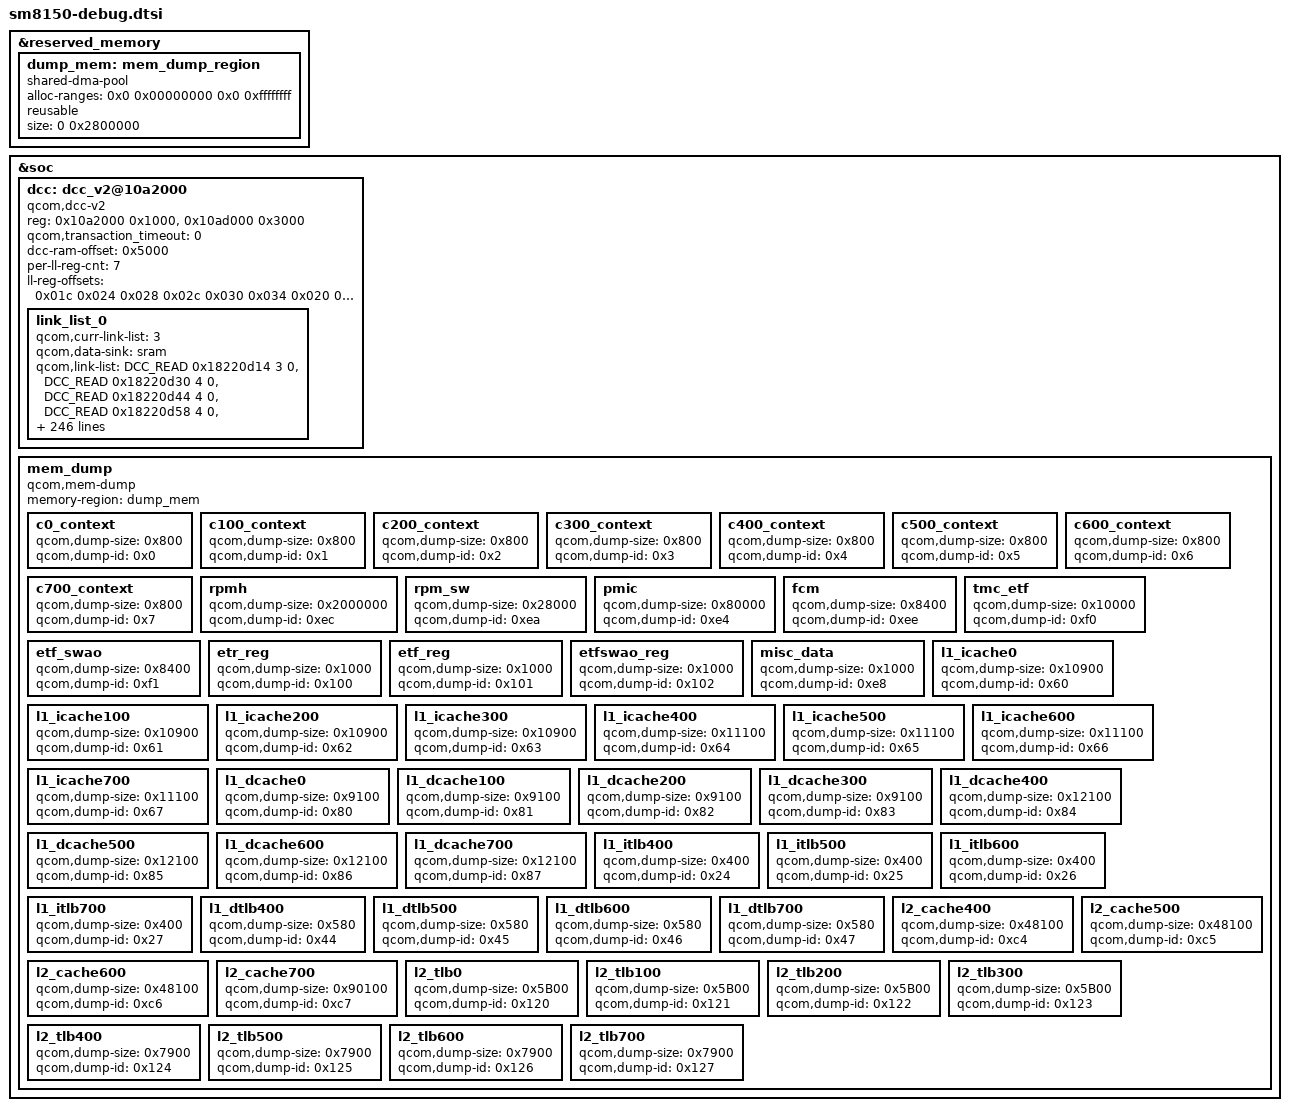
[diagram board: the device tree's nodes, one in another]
#include <dt-bindings/soc/qcom,dcc_v2.h>

&reserved_memory {
	#address-cells = <2>;
	#size-cells = <2>;
	ranges;

	dump_mem: mem_dump_region {
		compatible = "shared-dma-pool";
		alloc-ranges = <0x0 0x00000000 0x0 0xffffffff>;
		reusable;
		size = <0 0x2800000>;
	};
};

&soc {
	dcc: dcc_v2@10a2000 {
		compatible = "qcom,dcc-v2";
		reg = <0x10a2000 0x1000>,
		      <0x10ad000 0x3000>;
		reg-names = "dcc-base", "dcc-ram-base";

		qcom,transaction_timeout = <0>;

		dcc-ram-offset = <0x5000>;

		per-ll-reg-cnt = <7>;
		ll-reg-offsets = <
			0x01c 0x024 0x028 0x02c 0x030 0x034 0x020
			0x09c 0x0a4 0x0a8 0x0ac 0x0b0 0x0b4 0x0a0
			0x11c 0x124 0x128 0x12c 0x130 0x134 0x120
			0x19c 0x1a4 0x1a8 0x1ac 0x1b0 0x1b4 0x1a0
			0x21c 0x224 0x228 0x22c 0x230 0x234 0x220
			0x29c 0x2a4 0x2a8 0x2ac 0x2b0 0x2b4 0x2a0
			0x31c 0x324 0x328 0x32c 0x330 0x334 0x320
			0x39c 0x3a4 0x3a8 0x3ac 0x3b0 0x3b4 0x3a4>;

		link_list_0 {
			qcom,curr-link-list = <3>;
			qcom,data-sink = "sram";
			qcom,link-list = <DCC_READ 0x18220d14 3 0>,
						<DCC_READ 0x18220d30 4 0>,
						<DCC_READ 0x18220d44 4 0>,
						<DCC_READ 0x18220d58 4 0>,
						<DCC_READ 0x18220fb4 3 0>,
						<DCC_READ 0x18220fd0 4 0>,
						<DCC_READ 0x18220fe4 4 0>,
						<DCC_READ 0x18220ff8 4 0>,
						<DCC_READ 0x18220d04 1 0>,
						<DCC_READ 0x18220d00 1 0>,
						<DCC_READ 0x18000024 1 0>,
						<DCC_READ 0x18000040 3 0>,
						<DCC_READ 0x18010024 1 0>,
						<DCC_READ 0x18010040 3 0>,
						<DCC_READ 0x18020024 1 0>,
						<DCC_READ 0x18020040 3 0>,
						<DCC_READ 0x18030024 1 0>,
						<DCC_READ 0x18030040 3 0>,
						<DCC_READ 0x18040024 1 0>,
						<DCC_READ 0x18040040 3 0>,
						<DCC_READ 0x18050024 1 0>,
						<DCC_READ 0x18050040 3 0>,
						<DCC_READ 0x18060024 1 0>,
						<DCC_READ 0x18060040 3 0>,
						<DCC_READ 0x18070024 1 0>,
						<DCC_READ 0x18070040 3 0>,
						<DCC_READ 0x18080104 1 0>,
						<DCC_READ 0x18080168 1 0>,
						<DCC_READ 0x18080198 1 0>,
						<DCC_READ 0x18080128 1 0>,
						<DCC_READ 0x18080024 1 0>,
						<DCC_READ 0x18080040 3 0>,
						<DCC_READ 0x18200400 3 0>,
						<DCC_READ 0x0b201020 2 0>,
						<DCC_READ 0x18101908 1 0>,
						<DCC_READ 0x18101c18 1 0>,
						<DCC_READ 0x18390810 1 0>,
						<DCC_READ 0x18390c50 1 0>,
						<DCC_READ 0x18390814 1 0>,
						<DCC_READ 0x18390c54 1 0>,
						<DCC_READ 0x18390818 1 0>,
						<DCC_READ 0x18390c58 1 0>,
						<DCC_READ 0x18393a84 2 0>,
						<DCC_READ 0x18100908 1 0>,
						<DCC_READ 0x18100c18 1 0>,
						<DCC_READ 0x183a0810 1 0>,
						<DCC_READ 0x183a0c50 1 0>,
						<DCC_READ 0x183a0814 1 0>,
						<DCC_READ 0x183a0c54 1 0>,
						<DCC_READ 0x183a0818 1 0>,
						<DCC_READ 0x183a0c58 1 0>,
						<DCC_READ 0x183a3a84 2 0>,
						<DCC_READ 0x18393500 80 0>,
						<DCC_READ 0x183a3500 80 0>,
						<DCC_READ 0x09050008 1 0>,
						<DCC_READ 0x09050078 1 0>,
						<DCC_READ 0x09601000 1 0>,
						<DCC_READ 0x09601004 1 0>,
						<DCC_READ 0x09602000 1 0>,
						<DCC_READ 0x09602004 1 0>,
						<DCC_READ 0x09603000 1 0>,
						<DCC_READ 0x09603004 1 0>,
						<DCC_READ 0x09604000 1 0>,
						<DCC_READ 0x09604004 1 0>,
						<DCC_READ 0x09605000 1 0>,
						<DCC_READ 0x09605004 1 0>,
						<DCC_READ 0x09606000 1 0>,
						<DCC_READ 0x09606004 1 0>,
						<DCC_READ 0x09607000 1 0>,
						<DCC_READ 0x09607004 1 0>,
						<DCC_READ 0x09608000 1 0>,
						<DCC_READ 0x09608004 1 0>,
						<DCC_READ 0x09609000 1 0>,
						<DCC_READ 0x09609004 1 0>,
						<DCC_READ 0x0960a000 1 0>,
						<DCC_READ 0x0960a004 1 0>,
						<DCC_READ 0x0960b000 1 0>,
						<DCC_READ 0x0960b004 1 0>,
						<DCC_READ 0x0960c000 1 0>,
						<DCC_READ 0x0960c004 1 0>,
						<DCC_READ 0x0960d000 1 0>,
						<DCC_READ 0x0960d004 1 0>,
						<DCC_READ 0x0960e000 1 0>,
						<DCC_READ 0x0960e004 1 0>,
						<DCC_READ 0x0960f000 1 0>,
						<DCC_READ 0x0960f004 1 0>,
						<DCC_READ 0x09610000 1 0>,
						<DCC_READ 0x09610004 1 0>,
						<DCC_READ 0x09611000 1 0>,
						<DCC_READ 0x09611004 1 0>,
						<DCC_READ 0x09612000 1 0>,
						<DCC_READ 0x09612004 1 0>,
						<DCC_READ 0x09613000 1 0>,
						<DCC_READ 0x09613004 1 0>,
						<DCC_READ 0x09614000 1 0>,
						<DCC_READ 0x09614004 1 0>,
						<DCC_READ 0x09615000 1 0>,
						<DCC_READ 0x09615004 1 0>,
						<DCC_READ 0x09616000 1 0>,
						<DCC_READ 0x09616004 1 0>,
						<DCC_READ 0x09617000 1 0>,
						<DCC_READ 0x09617004 1 0>,
						<DCC_READ 0x09618000 1 0>,
						<DCC_READ 0x09618004 1 0>,
						<DCC_READ 0x09619000 1 0>,
						<DCC_READ 0x09619004 1 0>,
						<DCC_READ 0x0961a000 1 0>,
						<DCC_READ 0x0961a004 1 0>,
						<DCC_READ 0x0961b000 1 0>,
						<DCC_READ 0x0961b004 1 0>,
						<DCC_READ 0x0961c000 1 0>,
						<DCC_READ 0x0961c004 1 0>,
						<DCC_READ 0x0961d000 1 0>,
						<DCC_READ 0x0961d004 1 0>,
						<DCC_READ 0x0961e000 1 0>,
						<DCC_READ 0x0961e004 1 0>,
						<DCC_READ 0x0961f000 1 0>,
						<DCC_READ 0x0961f004 1 0>,
						<DCC_WRITE 0x06a0e00c 0x00600007 1>,
						<DCC_WRITE 0x06a0e01c 0x00136800 1>,
						<DCC_READ 0x06a0e014 1 1>,
						<DCC_WRITE 0x06a0e01c 0x00136810 1>,
						<DCC_READ 0x06a0e014 1 1>,
						<DCC_WRITE 0x06a0e01c 0x00136820 1>,
						<DCC_READ 0x06a0e014 1 1>,
						<DCC_WRITE 0x06a0e01c 0x00136830 1>,
						<DCC_READ 0x06a0e014 1 1>,
						<DCC_WRITE 0x06a0e01c 0x00136840 1>,
						<DCC_READ 0x06a0e014 1 1>,
						<DCC_WRITE 0x06a0e01c 0x00136850 1>,
						<DCC_READ 0x06a0e014 1 1>,
						<DCC_WRITE 0x06a0e01c 0x00136860 1>,
						<DCC_READ 0x06a0e014 1 1>,
						<DCC_WRITE 0x06a0e01c 0x00136870 1>,
						<DCC_READ 0x06a0e014 1 1>,
						<DCC_WRITE 0x06a0e01c 0x0003e9a0 1>,
						<DCC_WRITE 0x06a0e01c 0x001368a0 1>,
						<DCC_READ 0x06a0e014 1 1>,
						<DCC_WRITE 0x06a0e01c 0x0003c0a0 1>,
						<DCC_WRITE 0x06a0e01c 0x001368a0 1>,
						<DCC_READ 0x06a0e014 1 1>,
						<DCC_WRITE 0x06a0e01c 0x0003d1a0 1>,
						<DCC_WRITE 0x06a0e01c 0x001368a0 1>,
						<DCC_READ 0x06a0e014 1 1>,
						<DCC_WRITE 0x06a0e01c 0x0003d2a0 1>,
						<DCC_WRITE 0x06a0e01c 0x001368a0 1>,
						<DCC_READ 0x06a0e014 1 1>,
						<DCC_WRITE 0x06a0e01c 0x0003d5a0 1>,
						<DCC_WRITE 0x06a0e01c 0x001368a0 1>,
						<DCC_READ 0x06a0e014 1 1>,
						<DCC_WRITE 0x06a0e01c 0x0003d6a0 1>,
						<DCC_WRITE 0x06a0e01c 0x001368a0 1>,
						<DCC_READ 0x06a0e014 1 1>,
						<DCC_WRITE 0x06a0e01c 0x0003e8a0 1>,
						<DCC_WRITE 0x06a0e01c 0x001368a0 1>,
						<DCC_READ 0x06a0e014 1 1>,
						<DCC_WRITE 0x06a0e01c 0x0003eea0 1>,
						<DCC_WRITE 0x06a0e01c 0x001368a0 1>,
						<DCC_READ 0x06a0e014 1 1>,
						<DCC_WRITE 0x06a0e01c 0x0003b1a0 1>,
						<DCC_WRITE 0x06a0e01c 0x001368a0 1>,
						<DCC_READ 0x06a0e014 1 1>,
						<DCC_WRITE 0x06a0e01c 0x0003b2a0 1>,
						<DCC_WRITE 0x06a0e01c 0x001368a0 1>,
						<DCC_READ 0x06a0e014 1 1>,
						<DCC_WRITE 0x06a0e01c 0x0003b5a0 1>,
						<DCC_WRITE 0x06a0e01c 0x001368a0 1>,
						<DCC_READ 0x06a0e014 1 1>,
						<DCC_WRITE 0x06a0e01c 0x0003b6a0 1>,
						<DCC_WRITE 0x06a0e01c 0x001368a0 1>,
						<DCC_READ 0x06a0e014 1 1>,
						<DCC_WRITE 0x06a0e01c 0x0003c2a0 1>,
						<DCC_WRITE 0x06a0e01c 0x001368a0 1>,
						<DCC_READ 0x06a0e014 1 1>,
						<DCC_WRITE 0x06a0e01c 0x0003c5a0 1>,
						<DCC_WRITE 0x06a0e01c 0x001368a0 1>,
						<DCC_READ 0x06a0e014 1 1>,
						<DCC_WRITE 0x06a0e01c 0x0003c6a0 1>,
						<DCC_WRITE 0x06a0e01c 0x001368a0 1>,
						<DCC_READ 0x06a0e014 1 1>,
						<DCC_WRITE 0x06a0e014 0x00020b38 1>,
						<DCC_WRITE 0x06a0e01c 0x000368b0 1>,
						<DCC_WRITE 0x06a0e01c 0x00000ba8 1>,
						<DCC_WRITE 0x06a0e01c 0x0013b6a0 1>,
						<DCC_WRITE 0x06a0e01c 0x00f1e000 1>,
						<DCC_WRITE 0x06a0e008 0x00000007 1>,
						<DCC_READ 0x09067e00 124 0>,
						<DCC_WRITE 0x090c80f8 0x00000001 1>,
						<DCC_READ 0x091800c8 1 0>,
						<DCC_READ 0x09180740 1 0>,
						<DCC_READ 0x09183740 1 0>,
						<DCC_READ 0x091900c8 1 0>,
						<DCC_READ 0x09190740 1 0>,
						<DCC_READ 0x09193740 1 0>,
						<DCC_READ 0x09181254 2 0>,
						<DCC_READ 0x09181624 1 0>,
						<DCC_READ 0x09181740 1 0>,
						<DCC_READ 0x09181768 1 0>,
						<DCC_READ 0x0918182c 1 0>,
						<DCC_READ 0x09182254 2 0>,
						<DCC_READ 0x09182624 1 0>,
						<DCC_READ 0x09182740 1 0>,
						<DCC_READ 0x09182768 1 0>,
						<DCC_READ 0x0918282c 1 0>,
						<DCC_READ 0x09184254 2 0>,
						<DCC_READ 0x09184624 1 0>,
						<DCC_READ 0x09184740 1 0>,
						<DCC_READ 0x09184768 1 0>,
						<DCC_READ 0x0918482c 1 0>,
						<DCC_READ 0x09185254 2 0>,
						<DCC_READ 0x09185624 1 0>,
						<DCC_READ 0x09185740 1 0>,
						<DCC_READ 0x09185768 1 0>,
						<DCC_READ 0x0918582c 1 0>,
						<DCC_READ 0x09191254 2 0>,
						<DCC_READ 0x09191624 1 0>,
						<DCC_READ 0x09191740 1 0>,
						<DCC_READ 0x09191768 1 0>,
						<DCC_READ 0x0919182c 1 0>,
						<DCC_READ 0x09192254 2 0>,
						<DCC_READ 0x09192624 1 0>,
						<DCC_READ 0x09192740 1 0>,
						<DCC_READ 0x09192768 1 0>,
						<DCC_READ 0x0919282c 1 0>,
						<DCC_READ 0x09194254 2 0>,
						<DCC_READ 0x09194624 1 0>,
						<DCC_READ 0x09194740 1 0>,
						<DCC_READ 0x09194768 1 0>,
						<DCC_READ 0x0919482c 1 0>,
						<DCC_READ 0x09195254 2 0>,
						<DCC_READ 0x09195624 1 0>,
						<DCC_READ 0x09195740 1 0>,
						<DCC_READ 0x09195768 1 0>,
						<DCC_READ 0x0919582c 1 0>,
						<DCC_READ 0x09186048 1 0>,
						<DCC_READ 0x09186054 1 0>,
						<DCC_READ 0x09186164 1 0>,
						<DCC_READ 0x09186170 1 0>,
						<DCC_READ 0x09186410 1 0>,
						<DCC_READ 0x09186618 4 0>,
						<DCC_READ 0x091866e0 1 0>,
						<DCC_READ 0x09186700 2 0>,
						<DCC_READ 0x09196048 1 0>,
						<DCC_READ 0x09196054 1 0>,
						<DCC_READ 0x09196164 1 0>,
						<DCC_READ 0x09196170 1 0>,
						<DCC_READ 0x09196410 1 0>,
						<DCC_READ 0x09196618 4 0>,
						<DCC_READ 0x091966e0 1 0>,
						<DCC_READ 0x09196700 2 0>;
		};
	};

	mem_dump {
		compatible = "qcom,mem-dump";
		memory-region = <&dump_mem>;

		c0_context {
			qcom,dump-size = <0x800>;
			qcom,dump-id = <0x0>;
		};

		c100_context {
			qcom,dump-size = <0x800>;
			qcom,dump-id = <0x1>;
		};

		c200_context {
			qcom,dump-size = <0x800>;
			qcom,dump-id = <0x2>;
		};

		c300_context {
			qcom,dump-size = <0x800>;
			qcom,dump-id = <0x3>;
		};

		c400_context {
			qcom,dump-size = <0x800>;
			qcom,dump-id = <0x4>;
		};

		c500_context {
			qcom,dump-size = <0x800>;
			qcom,dump-id = <0x5>;
		};

		c600_context {
			qcom,dump-size = <0x800>;
			qcom,dump-id = <0x6>;
		};

		c700_context {
			qcom,dump-size = <0x800>;
			qcom,dump-id = <0x7>;
		};

		rpmh {
			qcom,dump-size = <0x2000000>;
			qcom,dump-id = <0xec>;
		};

		rpm_sw {
			qcom,dump-size = <0x28000>;
			qcom,dump-id = <0xea>;
		};

		pmic {
			qcom,dump-size = <0x80000>;
			qcom,dump-id = <0xe4>;
		};

		fcm {
			qcom,dump-size = <0x8400>;
			qcom,dump-id = <0xee>;
		};

		tmc_etf {
			qcom,dump-size = <0x10000>;
			qcom,dump-id = <0xf0>;
		};

		etf_swao {
			qcom,dump-size = <0x8400>;
			qcom,dump-id = <0xf1>;
		};

		etr_reg {
			qcom,dump-size = <0x1000>;
			qcom,dump-id = <0x100>;
		};

		etf_reg {
			qcom,dump-size = <0x1000>;
			qcom,dump-id = <0x101>;
		};

		etfswao_reg {
			qcom,dump-size = <0x1000>;
			qcom,dump-id = <0x102>;
		};

		misc_data {
			qcom,dump-size = <0x1000>;
			qcom,dump-id = <0xe8>;
		};

		l1_icache0 {
			qcom,dump-size = <0x10900>;
			qcom,dump-id = <0x60>;
		};

		l1_icache100 {
			qcom,dump-size = <0x10900>;
			qcom,dump-id = <0x61>;
		};

		l1_icache200 {
			qcom,dump-size = <0x10900>;
			qcom,dump-id = <0x62>;
		};

		l1_icache300 {
			qcom,dump-size = <0x10900>;
			qcom,dump-id = <0x63>;
		};

		l1_icache400 {
			qcom,dump-size = <0x11100>;
			qcom,dump-id = <0x64>;
		};

		l1_icache500 {
			qcom,dump-size = <0x11100>;
			qcom,dump-id = <0x65>;
		};

		l1_icache600 {
			qcom,dump-size = <0x11100>;
			qcom,dump-id = <0x66>;
		};

		l1_icache700 {
			qcom,dump-size = <0x11100>;
			qcom,dump-id = <0x67>;
		};

		l1_dcache0 {
			qcom,dump-size = <0x9100>;
			qcom,dump-id = <0x80>;
		};

		l1_dcache100 {
			qcom,dump-size = <0x9100>;
			qcom,dump-id = <0x81>;
		};

		l1_dcache200 {
			qcom,dump-size = <0x9100>;
			qcom,dump-id = <0x82>;
		};

		l1_dcache300 {
			qcom,dump-size = <0x9100>;
			qcom,dump-id = <0x83>;
		};

		l1_dcache400 {
			qcom,dump-size = <0x12100>;
			qcom,dump-id = <0x84>;
		};

		l1_dcache500 {
			qcom,dump-size = <0x12100>;
			qcom,dump-id = <0x85>;
		};

		l1_dcache600 {
			qcom,dump-size = <0x12100>;
			qcom,dump-id = <0x86>;
		};

		l1_dcache700 {
			qcom,dump-size = <0x12100>;
			qcom,dump-id = <0x87>;
		};

		l1_itlb400 {
			qcom,dump-size = <0x400>;
			qcom,dump-id = <0x24>;
		};

		l1_itlb500 {
			qcom,dump-size = <0x400>;
			qcom,dump-id = <0x25>;
		};

		l1_itlb600 {
			qcom,dump-size = <0x400>;
			qcom,dump-id = <0x26>;
		};

		l1_itlb700 {
			qcom,dump-size = <0x400>;
			qcom,dump-id = <0x27>;
		};

		l1_dtlb400 {
			qcom,dump-size = <0x580>;
			qcom,dump-id = <0x44>;
		};

		l1_dtlb500 {
			qcom,dump-size = <0x580>;
			qcom,dump-id = <0x45>;
		};

		l1_dtlb600 {
			qcom,dump-size = <0x580>;
			qcom,dump-id = <0x46>;
		};

		l1_dtlb700 {
			qcom,dump-size = <0x580>;
			qcom,dump-id = <0x47>;
		};

		l2_cache400 {
			qcom,dump-size = <0x48100>;
			qcom,dump-id = <0xc4>;
		};

		l2_cache500 {
			qcom,dump-size = <0x48100>;
			qcom,dump-id = <0xc5>;
		};

		l2_cache600 {
			qcom,dump-size = <0x48100>;
			qcom,dump-id = <0xc6>;
		};

		l2_cache700 {
			qcom,dump-size = <0x90100>;
			qcom,dump-id = <0xc7>;
		};

		l2_tlb0 {
			qcom,dump-size = <0x5B00>;
			qcom,dump-id = <0x120>;
		};

		l2_tlb100 {
			qcom,dump-size = <0x5B00>;
			qcom,dump-id = <0x121>;
		};

		l2_tlb200 {
			qcom,dump-size = <0x5B00>;
			qcom,dump-id = <0x122>;
		};

		l2_tlb300 {
			qcom,dump-size = <0x5B00>;
			qcom,dump-id = <0x123>;
		};

		l2_tlb400 {
			qcom,dump-size = <0x7900>;
			qcom,dump-id = <0x124>;
		};

		l2_tlb500 {
			qcom,dump-size = <0x7900>;
			qcom,dump-id = <0x125>;
		};

		l2_tlb600 {
			qcom,dump-size = <0x7900>;
			qcom,dump-id = <0x126>;
		};

		l2_tlb700 {
			qcom,dump-size = <0x7900>;
			qcom,dump-id = <0x127>;
		};
	};
};
